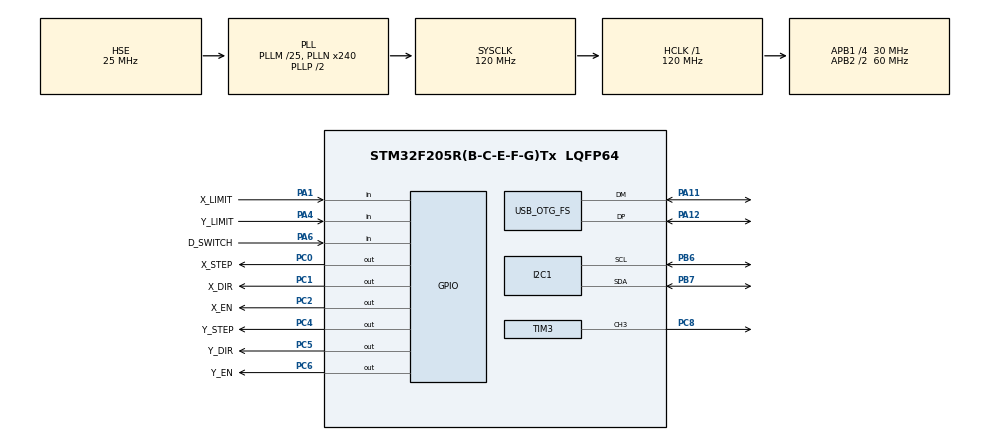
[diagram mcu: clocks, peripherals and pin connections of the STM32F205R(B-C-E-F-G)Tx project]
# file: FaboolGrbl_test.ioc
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Mcu.Family=STM32F2
Mcu.Name=STM32F205R(B-C-E-F-G)Tx
Mcu.Package=LQFP64
NVIC.OTG_FS_IRQn=true\:0\:0\:false
NVIC.PriorityGroup=NVIC_PRIORITYGROUP_4
PA1.GPIO_Label=X_LIMIT
PA1.Signal=GPIO_Input
PA11.Mode=Device_Only
PA11.Signal=USB_OTG_FS_DM
PA12.Mode=Device_Only
PA12.Signal=USB_OTG_FS_DP
PA13.Mode=JTAG(4-pin)
PA13.Signal=SYS_JTMS-SWDIO
PA14.Mode=JTAG(4-pin)
PA14.Signal=SYS_JTCK-SWCLK
PA15.Mode=JTAG(4-pin)
PA15.Signal=SYS_JTDI
PA4.GPIO_Label=Y_LIMIT
PA4.Signal=GPIO_Input
PA6.GPIO_Label=D_SWITCH
PA6.Signal=GPIO_Input
PB3.Mode=JTAG(4-pin)
PB3.Signal=SYS_JTDO-SWO
PB6.Mode=I2C
PB6.Signal=I2C1_SCL
PB7.Mode=I2C
PB7.Signal=I2C1_SDA
PC0.GPIO_Label=X_STEP
PC0.GPIO_Speed=GPIO_SPEED_HIGH
PC0.Signal=GPIO_Output
PC1.GPIO_Label=X_DIR
PC1.GPIO_Speed=GPIO_SPEED_HIGH
PC1.Signal=GPIO_Output
PC14-OSC32_IN.Mode=LSE-External-Oscillator
PC14-OSC32_IN.Signal=RCC_OSC32_IN
PC15-OSC32_OUT.Mode=LSE-External-Oscillator
PC15-OSC32_OUT.Signal=RCC_OSC32_OUT
PC2.GPIO_Label=X_EN
PC2.GPIO_Speed=GPIO_SPEED_HIGH
PC2.Signal=GPIO_Output
PC4.GPIO_Label=Y_STEP
PC4.GPIO_Speed=GPIO_SPEED_HIGH
PC4.Signal=GPIO_Output
PC5.GPIO_Label=Y_DIR
PC5.GPIO_Speed=GPIO_SPEED_HIGH
PC5.Signal=GPIO_Output
PC6.GPIO_Label=Y_EN
PC6.GPIO_Speed=GPIO_SPEED_HIGH
PC6.Signal=GPIO_Output
PC8.GPIO_Speed=GPIO_SPEED_HIGH
PC8.Signal=S_TIM3_CH3
PH0-OSC_IN.Mode=HSE-External-Oscillator
PH0-OSC_IN.Signal=RCC_OSC_IN
PH1-OSC_OUT.Mode=HSE-External-Oscillator
PH1-OSC_OUT.Signal=RCC_OSC_OUT
ProjectManager.HeapSize=0x400
ProjectManager.StackSize=0x200
ProjectManager.TargetToolchain=SW4STM32
RCC.48MHZClocksFreq_Value=48000000
RCC.AHBFreq_Value=120000000
RCC.APB1CLKDivider=RCC_HCLK_DIV4
RCC.APB1Freq_Value=30000000
RCC.APB1TimFreq_Value=60000000
RCC.APB2CLKDivider=RCC_HCLK_DIV2
RCC.APB2Freq_Value=60000000
RCC.APB2TimFreq_Value=120000000
RCC.CortexFreq_Value=120000000
RCC.HCLKFreq_Value=120000000
RCC.HSE_VALUE=25000000
RCC.HSI_VALUE=16000000
RCC.PLLM=25
RCC.PLLN=240
RCC.PLLQ=5
RCC.SYSCLKFreq_VALUE=120000000
RCC.SYSCLKSource=RCC_SYSCLKSOURCE_PLLCLK
RCC.VCOOutputFreq_Value=240000000
SH.S_TIM3_CH3.0=TIM3_CH3,PWM Generation3 CH3
TIM3.Channel-PWM\ Generation3\ CH3=TIM_CHANNEL_3
USB_DEVICE.CLASS_NAME-CDC_FS=CDC
USB_DEVICE.USBD_HandleTypeDef-CDC_FS=hUsbDeviceFS
USB_DEVICE.VirtualMode-CDC_FS=Cdc
USB_DEVICE.VirtualModeFS=Cdc_FS
USB_OTG_FS.VirtualMode=Device_Only
USB_OTG_FS.vbus_sensing_enable=DISABLE
VP_USB_DEVICE_VS_USB_DEVICE_CDC_FS.Mode=CDC_FS
board=FaboolGrbl_test

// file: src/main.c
/**
  ******************************************************************************
  * File Name          : main.c
  * Description        : Main program body
  ******************************************************************************
  *
  * COPYRIGHT(c) 2016 STMicroelectronics
  *
  * Redistribution and use in source and binary forms, with or without modification,
  * are permitted provided that the following conditions are met:
  *   1. Redistributions of source code must retain the above copyright notice,
  *      this list of conditions and the following disclaimer.
  *   2. Redistributions in binary form must reproduce the above copyright notice,
  *      this list of conditions and the following disclaimer in the documentation
  *      and/or other materials provided with the distribution.
  *   3. Neither the name of STMicroelectronics nor the names of its contributors
  *      may be used to endorse or promote products derived from this software
  *      without specific prior written permission.
  *
  * THIS SOFTWARE IS PROVIDED BY THE COPYRIGHT HOLDERS AND CONTRIBUTORS "AS IS"
  * AND ANY EXPRESS OR IMPLIED WARRANTIES, INCLUDING, BUT NOT LIMITED TO, THE
  * IMPLIED WARRANTIES OF MERCHANTABILITY AND FITNESS FOR A PARTICULAR PURPOSE ARE
  * DISCLAIMED. IN NO EVENT SHALL THE COPYRIGHT HOLDER OR CONTRIBUTORS BE LIABLE
  * FOR ANY DIRECT, INDIRECT, INCIDENTAL, SPECIAL, EXEMPLARY, OR CONSEQUENTIAL
  * DAMAGES (INCLUDING, BUT NOT LIMITED TO, PROCUREMENT OF SUBSTITUTE GOODS OR
  * SERVICES; LOSS OF USE, DATA, OR PROFITS; OR BUSINESS INTERRUPTION) HOWEVER
  * CAUSED AND ON ANY THEORY OF LIABILITY, WHETHER IN CONTRACT, STRICT LIABILITY,
  * OR TORT (INCLUDING NEGLIGENCE OR OTHERWISE) ARISING IN ANY WAY OUT OF THE USE
  * OF THIS SOFTWARE, EVEN IF ADVISED OF THE POSSIBILITY OF SUCH DAMAGE.
  *
  ******************************************************************************
  */
#include "stm32f2xx_hal.h"
#include "usb_device.h"

/* USER CODE BEGIN Includes */
#include "usbd_cdc_if.h"
#include "gcode.h"
/* USER CODE END Includes */

I2C_HandleTypeDef hi2c1;

TIM_HandleTypeDef htim3;

/* USER CODE BEGIN PV */
/* Private variables ---------------------------------------------------------*/

/* USER CODE END PV */

void SystemClock_Config(void);
static void MX_GPIO_Init(void);
static void MX_I2C1_Init(void);
static void MX_TIM3_Init(void);

void HAL_TIM_MspPostInit(TIM_HandleTypeDef *htim);

/* USER CODE BEGIN PFP */
/* Private function prototypes -----------------------------------------------*/

/* USER CODE END PFP */

int main(void)
{

  /* MCU Configuration----------------------------------------------------------*/

  /* Reset of all peripherals, Initializes the Flash interface and the Systick. */
  HAL_Init();

  /* Configure the system clock */
  SystemClock_Config();

  /* Initialize all configured peripherals */
  MX_GPIO_Init();
  MX_I2C1_Init();
  MX_TIM3_Init();
  MX_USB_DEVICE_Init();

  /* Infinite loop */
  /* USER CODE BEGIN WHILE */
  while (1)
  {
	if (hUsbDeviceFS.dev_state != USBD_STATE_CONFIGURED)
	{
		continue;
	}
	// Gコード処理
	gcode_process_line();

  /* USER CODE END WHILE */

  }

}

/** System Clock Configuration
*/
void SystemClock_Config(void)
{

  RCC_OscInitTypeDef RCC_OscInitStruct;
  RCC_ClkInitTypeDef RCC_ClkInitStruct;

  RCC_OscInitStruct.OscillatorType = RCC_OSCILLATORTYPE_HSE;
  RCC_OscInitStruct.HSEState = RCC_HSE_ON;
  RCC_OscInitStruct.PLL.PLLState = RCC_PLL_ON;
  RCC_OscInitStruct.PLL.PLLSource = RCC_PLLSOURCE_HSE;
  RCC_OscInitStruct.PLL.PLLM = 25;
  RCC_OscInitStruct.PLL.PLLN = 240;
  RCC_OscInitStruct.PLL.PLLP = RCC_PLLP_DIV2;
  RCC_OscInitStruct.PLL.PLLQ = 5;
  HAL_RCC_OscConfig(&RCC_OscInitStruct);

  RCC_ClkInitStruct.ClockType = RCC_CLOCKTYPE_HCLK|RCC_CLOCKTYPE_SYSCLK
                              |RCC_CLOCKTYPE_PCLK1|RCC_CLOCKTYPE_PCLK2;
  RCC_ClkInitStruct.SYSCLKSource = RCC_SYSCLKSOURCE_PLLCLK;
  RCC_ClkInitStruct.AHBCLKDivider = RCC_SYSCLK_DIV1;
  RCC_ClkInitStruct.APB1CLKDivider = RCC_HCLK_DIV4;
  RCC_ClkInitStruct.APB2CLKDivider = RCC_HCLK_DIV2;
  HAL_RCC_ClockConfig(&RCC_ClkInitStruct, FLASH_LATENCY_3);

  HAL_SYSTICK_Config(HAL_RCC_GetHCLKFreq()/1000);

  HAL_SYSTICK_CLKSourceConfig(SYSTICK_CLKSOURCE_HCLK);

  /* SysTick_IRQn interrupt configuration */
  HAL_NVIC_SetPriority(SysTick_IRQn, 0, 0);
}

/* I2C1 init function */
void MX_I2C1_Init(void)
{

  hi2c1.Instance = I2C1;
  hi2c1.Init.ClockSpeed = 100000;
  hi2c1.Init.DutyCycle = I2C_DUTYCYCLE_2;
  hi2c1.Init.OwnAddress1 = 0;
  hi2c1.Init.AddressingMode = I2C_ADDRESSINGMODE_7BIT;
  hi2c1.Init.DualAddressMode = I2C_DUALADDRESS_DISABLED;
  hi2c1.Init.OwnAddress2 = 0;
  hi2c1.Init.GeneralCallMode = I2C_GENERALCALL_DISABLED;
  hi2c1.Init.NoStretchMode = I2C_NOSTRETCH_DISABLED;
  HAL_I2C_Init(&hi2c1);

}

/* TIM3 init function */
void MX_TIM3_Init(void)
{

  TIM_MasterConfigTypeDef sMasterConfig;
  TIM_OC_InitTypeDef sConfigOC;

  htim3.Instance = TIM3;
  htim3.Init.Prescaler = (SystemCoreClock / 2 / 10000000) - 1;
  htim3.Init.CounterMode = TIM_COUNTERMODE_UP;
  htim3.Init.Period = 1000;
  htim3.Init.ClockDivision = TIM_CLOCKDIVISION_DIV1;
  HAL_TIM_PWM_Init(&htim3);

  sMasterConfig.MasterOutputTrigger = TIM_TRGO_RESET;
  sMasterConfig.MasterSlaveMode = TIM_MASTERSLAVEMODE_DISABLE;
  HAL_TIMEx_MasterConfigSynchronization(&htim3, &sMasterConfig);

  sConfigOC.OCMode = TIM_OCMODE_PWM1;
  sConfigOC.Pulse = 300;
  sConfigOC.OCPolarity = TIM_OCPOLARITY_HIGH;
  sConfigOC.OCFastMode = TIM_OCFAST_DISABLE;
  HAL_TIM_PWM_ConfigChannel(&htim3, &sConfigOC, TIM_CHANNEL_3);

  HAL_TIM_MspPostInit(&htim3);

}

/** Configure pins as
        * Analog
        * Input
        * Output
        * EVENT_OUT
        * EXTI
*/
void MX_GPIO_Init(void)
{

  GPIO_InitTypeDef GPIO_InitStruct;

  /* GPIO Ports Clock Enable */
  __GPIOC_CLK_ENABLE();
  __GPIOH_CLK_ENABLE();
  __GPIOA_CLK_ENABLE();
  __GPIOB_CLK_ENABLE();

  /*Configure GPIO pin Output Level */
  HAL_GPIO_WritePin(GPIOC, X_STEP_Pin|X_DIR_Pin|X_EN_Pin|Y_STEP_Pin
                          |Y_DIR_Pin|Y_EN_Pin, GPIO_PIN_RESET);

  /*Configure GPIO pins : X_STEP_Pin X_DIR_Pin X_EN_Pin Y_STEP_Pin
                           Y_DIR_Pin Y_EN_Pin */
  GPIO_InitStruct.Pin = X_STEP_Pin|X_DIR_Pin|X_EN_Pin|Y_STEP_Pin
                          |Y_DIR_Pin|Y_EN_Pin;
  GPIO_InitStruct.Mode = GPIO_MODE_OUTPUT_PP;
  GPIO_InitStruct.Pull = GPIO_NOPULL;
  GPIO_InitStruct.Speed = GPIO_SPEED_HIGH;
  HAL_GPIO_Init(GPIOC, &GPIO_InitStruct);

  /*Configure GPIO pins : X_LIMIT_Pin Y_LIMIT_Pin D_SWITCH_Pin */
  GPIO_InitStruct.Pin = X_LIMIT_Pin|Y_LIMIT_Pin|D_SWITCH_Pin;
  GPIO_InitStruct.Mode = GPIO_MODE_INPUT;
  GPIO_InitStruct.Pull = GPIO_NOPULL;
  HAL_GPIO_Init(GPIOA, &GPIO_InitStruct);

}

/************************ (C) COPYRIGHT STMicroelectronics *****END OF FILE****/
